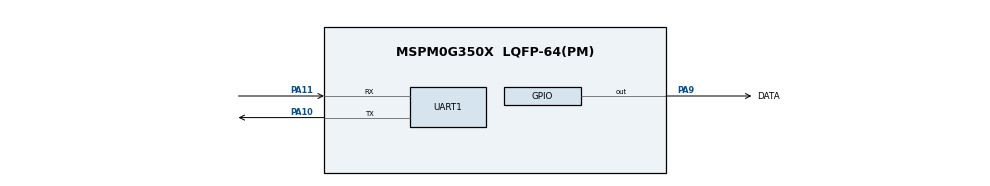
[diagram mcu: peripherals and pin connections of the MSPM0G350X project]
/**
 * @cliArgs --device "MSPM0G350X" --part "Default" --package "LQFP-64(PM)" --product "mspm0_sdk@2.10.00.04"
 * @versions {"tool":"1.27.0+4565"}
 */

/**
 * Import the modules used in this configuration.
 */
const GPIO   = scripting.addModule("/ti/driverlib/GPIO", {}, false);
const GPIO1  = GPIO.addInstance();
const SYSCTL = scripting.addModule("/ti/driverlib/SYSCTL");
const UART   = scripting.addModule("/ti/driverlib/UART", {}, false);
const UART1  = UART.addInstance();

/**
 * Write custom configuration values to the imported modules.
 */
GPIO1.port                               = "PORTA";
GPIO1.$name                              = "DHT11";
GPIO1.associatedPins[0].$name            = "DATA";
GPIO1.associatedPins[0].initialValue     = "SET";
GPIO1.associatedPins[0].ioStructure      = "HS";
GPIO1.associatedPins[0].assignedPin      = "9";
GPIO1.associatedPins[0].internalResistor = "PULL_UP";
GPIO1.associatedPins[0].pin.$assign      = "PA9";

const Board = scripting.addModule("/ti/driverlib/Board", {}, false);

SYSCTL.forceDefaultClkConfig = true;

UART1.$name                    = "UART_0";
UART1.peripheral.$assign       = "UART0";
UART1.peripheral.rxPin.$assign = "PA11";
UART1.peripheral.txPin.$assign = "PA10";
UART1.txPinConfig.$name        = "ti_driverlib_gpio_GPIOPinGeneric0";
UART1.rxPinConfig.$name        = "ti_driverlib_gpio_GPIOPinGeneric1";

/**
 * Pinmux solution for unlocked pins/peripherals. This ensures that minor changes to the automatic solver in a future
 * version of the tool will not impact the pinmux you originally saw.  These lines can be completely deleted in order to
 * re-solve from scratch.
 */
Board.peripheral.$suggestSolution          = "DEBUGSS";
Board.peripheral.swclkPin.$suggestSolution = "PA20";
Board.peripheral.swdioPin.$suggestSolution = "PA19";
SYSCTL.peripheral.$suggestSolution         = "SYSCTL";
